AUTOSAR XML (schema 4-2-2)
package /AUTOLIV/SoftwareComponents/SAD
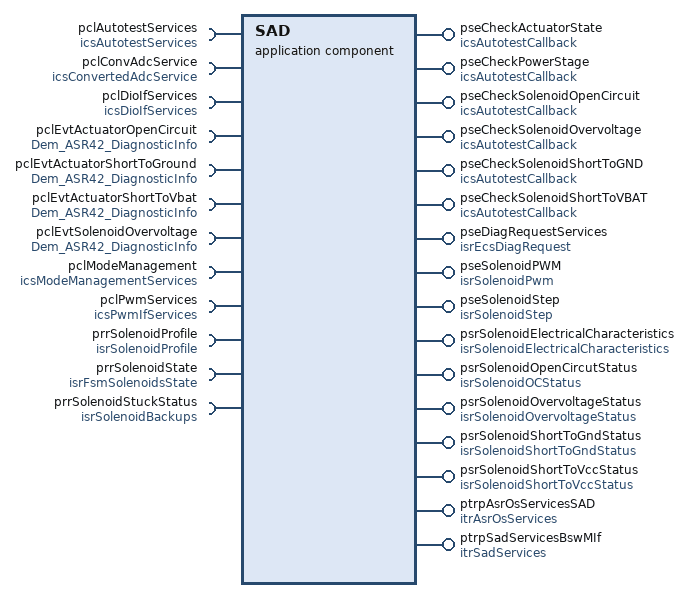
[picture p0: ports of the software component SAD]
  application sw component type SAD: category=SWC  # SAD_AC_SolenoidAbstractionDriver
    12 x require port:
      pclAutotestServices: required-com-specs=[GetCriticalAutoTestsReachedFlag, GetTestResult], required-interface=icsAutotestServices  # # Architecture Element ID ARCH_SW_SAD_pclAutotestServices # Description - The interface shall be used to read different autotests results by passing the {Autotest Id} to the input parameter and reading the {Autotest Result} output parameter. # Data Flow ## Inputs - {Autotest Id} • Can be: - One of the autotest id value between [0...17] ## Outputs - {Autotest Result} • Can be OK, NOK, NOT DECIDED, NON_EXISTENT, BAD_CONDITIONS #Linked Runnable - SAD_CheckSolenoidShortToVBATAutotest - SAD_CheckSolenoidShortToGNDAutotest - SAD_CheckSolenoidOpenCircuitAutotest - SAD_CheckSolenoidOvervoltage - SAD_CheckPowerStage # Traceability
      pclConvAdcService: client-com-spec=getMeasure, required-interface=icsConvertedAdcService  # # Architecture Element ID ARCH_SW_SAD_pclConvAdcService # Description - The interface shall be used to read the KL30 voltage level in mV # Data Flow ## Inputs ## Outputs - {KL30 Voltage in mV} #Linked Runnable - SAD_runMainFunction - SAD_CheckSolenoidOpenCircuitAutotest - SAD_CheckSolenoidShortToGNDAutotest - SAD_CheckSolenoidShortToVBATAutotest - SAD_CheckSolenoidOvervoltage # Traceability
      pclDioIfServices: required-com-specs=[ReadChannel, WriteChannel], required-interface=icsDioIfServices  # # Architecture Element ID ARCH_SW_SAD_pclDioIfServices # Description - The interface shall be used to set the {Digital Pin Level} of a certain {Pin ID}; - The interface shall be used to Read the {Pin ID} of a certain {Pin Digital Level}; # Data Flow ## Inputs - {Digital Pin Level} - Can be STD_HIGH, STD_LOW - {Pin ID} - Can be: - DIOIF_CH_EN_CS_X - The Solenoid enable pin wher 'X' is the ID of solenoid; - DIOIF_CH_ON_OFF_POWER - The ID of general swithc of solenoids circuit; - DIOIF_CH_EN_BOOST - The ID of enebling boost circuit; ## Outputs - {Pin Digital Level} - Can be STD_HIGH, STD_LOW #Linked Runnable - SAD_CheckPowerStage - SAD_runMainFunction # Traceability DOM_eCS_TF_R_173;
      pclEvtActuatorOpenCircuit: required-interface=Dem_ASR42_DiagnosticInfo  # # Architecture Element ID - ARCH_SW_SAD_pclEvtActuatorOpenCircuit # Description - The RTE port shall be used to read the status of the Open Circuit Event using the output variable {Event Status}. # Data Flow ## Inputs ## Outputs - {Event Status} • Can be one or more combination of the following values: - DEM_UDS_STATUS_TF - DEM_UDS_STATUS_TFTOC - DEM_UDS_STATUS_PDTC - DEM_UDS_STATUS_CDTC - DEM_UDS_STATUS_TNCSLC - DEM_UDS_STATUS_TFSLC - DEM_UDS_STATUS_TNCTOC - DEM_UDS_STATUS_WIR # Linked Runnable - SAD_CheckSolenoidOpenCircuitAutotest #Traceability
        required-com-specs:
          GetEventStatus
          GetEventFailed
          GetEventTested
          GetDTCOfEvent
          GetFaultDetectionCounter
          GetEventFreezeFrameData
          GetEventExtendedDataRecord
          GetDebouncingOfEvent
          GetEventExtendedDataRecordEx
          GetEventFreezeFrameDataEx
      pclEvtActuatorShortToGround: required-interface=Dem_ASR42_DiagnosticInfo  # # Architecture Element ID - ARCH_SW_SAD_pclEvtActuatorShortToGround # Description - The RTE port shall be used to read the status of the Short Circuit to Ground Event using the output variable {Event Status}. # Data Flow ## Inputs ## Outputs - {Event Status} • Can be one or more combination of the following values: - DEM_UDS_STATUS_TF - DEM_UDS_STATUS_TFTOC - DEM_UDS_STATUS_PDTC - DEM_UDS_STATUS_CDTC - DEM_UDS_STATUS_TNCSLC - DEM_UDS_STATUS_TFSLC - DEM_UDS_STATUS_TNCTOC - DEM_UDS_STATUS_WIR # Linked Runnable - SAD_CheckSolenoidShortToGNDAutotest #Traceability
        required-com-specs:
          GetEventStatus
          GetEventFailed
          GetEventTested
          GetDTCOfEvent
          GetFaultDetectionCounter
          GetEventFreezeFrameData
          GetEventExtendedDataRecord
          GetDebouncingOfEvent
          GetEventExtendedDataRecordEx
          GetEventFreezeFrameDataEx
      pclEvtActuatorShortToVbat: required-interface=Dem_ASR42_DiagnosticInfo  # # Architecture Element ID - ARCH_SW_SAD_pclEvtActuatorShortToVbat # Description - The RTE port shall be used to read the status of the Short Circuit to Ground Event using the output variable {Event Status}. # Data Flow ## Inputs ## Outputs - {Event Status} • Can be one or more combination of the following values: - DEM_UDS_STATUS_TF - DEM_UDS_STATUS_TFTOC - DEM_UDS_STATUS_PDTC - DEM_UDS_STATUS_CDTC - DEM_UDS_STATUS_TNCSLC - DEM_UDS_STATUS_TFSLC - DEM_UDS_STATUS_TNCTOC - DEM_UDS_STATUS_WIR # Linked Runnable - SAD_CheckSolenoidShortToVBATAutotest #Traceability
        required-com-specs:
          GetEventStatus
          GetEventFailed
          GetEventTested
          GetDTCOfEvent
          GetFaultDetectionCounter
          GetEventFreezeFrameData
          GetEventExtendedDataRecord
          GetDebouncingOfEvent
          GetEventExtendedDataRecordEx
          GetEventFreezeFrameDataEx
      pclEvtSolenoidOvervoltage: required-interface=Dem_ASR42_DiagnosticInfo  # # Architecture Element ID - ARCH_SW_SAD_pclEvtSolenoidOvervoltage # Description - The RTE port shall be used to read the status of the Solenoid Over Voltage Event using the output variable {Event Status}. # Data Flow ## Inputs ## Outputs - {Event Status} • Can be one or more combination of the following values: - DEM_UDS_STATUS_TF - DEM_UDS_STATUS_TFTOC - DEM_UDS_STATUS_PDTC - DEM_UDS_STATUS_CDTC - DEM_UDS_STATUS_TNCSLC - DEM_UDS_STATUS_TFSLC - DEM_UDS_STATUS_TNCTOC - DEM_UDS_STATUS_WIR # Linked Runnable - SAD_CheckSolenoidOvervoltage #Traceability
        required-com-specs:
          GetEventStatus
          GetEventFailed
          GetEventTested
          GetDTCOfEvent
          GetFaultDetectionCounter
          GetEventFreezeFrameData
          GetEventExtendedDataRecord
          GetDebouncingOfEvent
          GetEventExtendedDataRecordEx
          GetEventFreezeFrameDataEx
      pclModeManagement: client-com-spec=CheckModeStatus, required-interface=icsModeManagementServices  # # Architecture Element ID ARCH_SW_SAD_pclModeManagement # Description - The interface shall be used to read different statuses regarding the solenoid states by passing the {Mode Status Flag} to the input parameter and reading the {Mode Status} output parameter. # Data Flow ## Inputs - {Mode Status Flag} • Can be: - CRITICAL_AUTOTESTS_IN_PROGRESS; - NVM_BLOCK_RESTORE_IN_PROGRESS; - SOLENOID_X_DISABLED; - SOLENOID_X_BUCKLE_LATCHED; - SOLENOID_X_UNLOCK_CONFIRMED; - ECU_PERMANENT_HW_ERROR; - ECU_SPORADIC_ERROR; - CAN_INHIB_STATUS; * Where X represents the solenoid number and can take the value between [1..6]; ## Outputs - {Mode Status} • Can be TRUE, FALSE #Linked Runnable - SAD_runMainFunction # Traceability
      pclPwmServices: required-com-specs=[DisablePWM, EnablePWM, SetDutyCycle], required-interface=icsPwmIfServices  # # Architecture Element ID ARCH_SW_SAD_pclPwmServices # Description - The interface shall be used to set the {PWM Duty Cycle Value} of a certain {Solenoid Channel ID} # Data Flow ## Inputs - {Solenoid Channel ID} - {PWM Duty Cycle Value} ## Outputs #Linked Runnable - SAD_runMainFunction # Traceability
      prrSolenoidProfile: nonqueued-receiver-com-spec{data-element=au8SelectedProfile, enable-update=true, init-value=6 x KU8_PROFILE_UNLOCK}, required-interface=isrSolenoidProfile  # # Architecture Element ID ARCH_SW_SAD_prrSolenoidProfile # Description - The interface shall be used to read the profile(collection of steps) nb. that should be executed by the SAD module for each solenoid. # Data Flow ## Inputs ## Outputs - {Profile for Solenoid x} (valid for all solenoids) • Can be: - 00h - UNLOCK; - 01h - BACKUP; - 02h - DIAGNOSTIC; - FFh - NO_PROFILE; #Linked Runnable - SAD_runMainFunction # Traceability
      prrSolenoidState: nonqueued-receiver-com-spec{data-element=au8SolenoidState, init-value=6 x KU8_LOCK_STATE}, required-interface=isrFsmSolenoidsState
      prrSolenoidStuckStatus: nonqueued-receiver-com-spec{data-element=au8SolenoidIsStuck, enable-update=true, init-value=6 x 0}, required-interface=isrSolenoidBackups  # # Architecture Element ID - ARCH_SW_SAD_prrSolenoidStuckStatus_SAD_checkActuatorState # Description - The runnable shall read on {Solenoid Stuck Status} the current stuck status of each solenoid. # Data Flow ## Inputs ## Outputs - {Solenoid Stuck Status} - Can be KU8_FALSE - if the solenoid is NOT stuck; - Can be KU8_TRUE - if the solenoid is stuck; # Linked Runnable - SAD_checkActuatorState #Traceability DOM_eCS_TF_H_233, DOM_eCS_TF_H_234, DOM_eCS_TF_H_235
    16 x provide port:
      pseCheckActuatorState: server-com-spec{operation=AutotestCallback, queue-length=1}, provided-interface=icsAutotestCallback  # # Architecture Element ID - ARCH_SW_SAD_pseCheckActuatorState_SAD_checkActuatorState # Description - The auto-test shall detect if the solenoid lever is mechanically blocked - If the number of executed backup profiles from the {Nb. of Executed Backups} input parameter is higher or equal than the {Executed Backup Threshold} then the auto-test shall return NOK on the {Autotest Result} output parameter - If the buckle status coresponding to the tested solenoid is not latched, then the auto-test result shall be forced to OK - If the solenoid is disabled via the {Solenoid Variant Coding} then the actuator blocked conditions will not be checked # Data Flow ## Inputs - {Nb. of Executed Backups} - {Executed Backup Threshold} - {Solenoid Variant Coding} - {Buckle Status} ## Outputs - {Autotest Result} - Can be one of the following values: OK, NOK, NOT DECIDED # Linked Runnable - SAD_checkActuatorState #Traceability DOM_eCS_TF_H_233, DOM_eCS_TF_H_234, DOM_eCS_TF_H_235
      pseCheckPowerStage: server-com-spec{operation=AutotestCallback, queue-length=1}, provided-interface=icsAutotestCallback  # # Architecture Element ID - ARCH_SW_SAD_pseCheckPowerStage_SAD_CheckPowerStage # Description - The auto-test shall check the states of relevant pins involved in the solenoid control circuit. The auto-test will check the next situations: - If profile UNLOCK or BACKUP is active and reached the finishing step: - On-Off pin should be HIGH; - Boost Enable pin should be LOW; - Solenoid enable pin should be LOW; - If profile DIAGNOSTIC is active : - On-Off pin should be HIGH; - Boost Enable pin should be HIGH; - Solenoid enable pin should be LOW; - If profile LOCK is active on all enabled solenoids: - On-Off pin should be LOW; - Boost Enable pin should be HIGH; - Solenoid enable pin should be HIGH; # Data Flow ## Inputs ## Outputs - {Autotest Result} - Can be one of the following values: OK, NOK, NOT DECIDED # Linked Runnable - SAD_CheckPowerStage #Traceability DOM_eCS_TF_H_398 DOM_eCS_TF_H_399 DOM_eCS_TF_H_400 DOM_eCS_TF_H_401 DOM_eCS_TF_H_402 DOM_eCS_TF_H_403 DOM_eCS_TF_H_378
      pseCheckSolenoidOpenCircuit: server-com-spec{operation=AutotestCallback, queue-length=1}, provided-interface=icsAutotestCallback  # # Architecture Element ID - ARCH_SW_SAD_pseCheckSolenoidOpenCircuit_SAD_CheckSolenoidOpenCircuitAutotest # Description - The auto-test shall detect for all conected and configured solenoids if they are electrically conected. - In order to detect an open-circuit hardware fault, all measurements on solenoid ADC lines shall be done with unlock profile or diagnostic profile active. - If the measured solenoid voltage is lower or equal than {NVP_u16OpenCircuitUnlockHighThrs} when unlock profile is active and step profile is different than infinite step, than autotest shall return OK. - If the measured solenoid voltage is greater than {NVP_u16OpenCircuitUnlockHighThrs} when unlock profile is active and step profile is different than infinite step, than autotest shall return NOK. - If the measured solenoid voltage is in range between +25% of {VBATMeasuredVoltage} and -25% of {VBATMeasuredVoltage} when unlock profile is active and step profile is equal to infinite step, than autotest shall return OK. - If the measured solenoid voltage is not in range between +25% of {VBATMeasuredVoltage} and -25% of {VBATMeasuredVoltage} when unlock profile is active and step profile is equal to infinite step, than autotest shall return NOK. - If the measured solenoid voltage is in range between +20% of {NVP_u16OpenCircuitDiagProfThrs} and -20% of {NVP_u16OpenCircuitDiagProfThrs} when diagnostic profile is active, than autotest shall return OK. - If the measured solenoid voltage is not in range between +20% of {NVP_u16OpenCircuitDiagProfThrs} and -20% of {NVP_u16OpenCircuitDiagProfThrs} when diagnostic profile is active, than autotest shall NOK. - If unlock profile or diagnostic profile is not active, than autotest shall return last valid autotest result. # Data Flow ## Inputs - {NVP_u16OpenCircuitUnlockHighThrs} - {VBATMeasuredVoltage} - {NVP_u16OpenCircuitDiagProfThrs} ## Outputs - {Autotest Result} - Can be one of the following values: OK, NOK, NOT DECIDED # Linked Runnable - SAD_CheckSolenoidOpenCircuitAutotest #Traceability DOM_eCS_TF_H_260, DOM_eCS_TF_H_261, DOM_eCS_TF_H_259, DOM_eCS_TF_H_265, DOM_eCS_TF_H_256
      pseCheckSolenoidOvervoltage: server-com-spec{operation=AutotestCallback, queue-length=1}, provided-interface=icsAutotestCallback  # # Architecture Element ID - ARCH_SW_SAD_pseCheckSolenoidOvervoltage_SAD_CheckSolenoidOvervoltage # Description - The auto-test shall detect all connected and configured solenoids if they didn't exceed an NVP Configurable voltage Threshold when they have an active profile: - If UNLOCK or BACKUP profile is active and the infinite step is reached: - If the measured solenoid voltage is lower than NVP_u16OvervoltageUnlockProfThrs when unlock profile is active, than autotest shall return OK. - If the measured solenoid voltage is greater or equal to NVP_u16OvervoltageUnlockProfThrs when unlock profile is active, than autotest shall return NOK. - If DIAGNOSTIC profile is active : - If the measured solenoid voltage is lower than NVP_u16OvervoltageDiagProfThrs when diagnostic profile is active, than autotest shall return OK. - If the measured solenoid voltage is greater or equal to NVP_u16OvervoltageDiagProfThrs when diagnostic profile is active, than autotest shall return NOK. - If NO profile is active (LOCK): - If unlock profile or diagnostic profile is not active, than autotest shall return last valid autotest result. # Data Flow ## Outputs - {Autotest Result} - Can be one of the following values: OK, NOK, NOT DECIDED # Linked Runnable - SAD_CheckSolenoidOvervoltage #Traceability DOM_eCS_TF_H_392 DOM_eCS_TF_H_393 DOM_eCS_TF_H_394 DOM_eCS_TF_H_396 DOM_eCS_TF_H_397 DOM_eCS_TF_H_381
      pseCheckSolenoidShortToGND: server-com-spec{operation=AutotestCallback, queue-length=1}, provided-interface=icsAutotestCallback  # # Architecture Element ID - ARCH_SW_SAD_pseCheckSolenoidShortToGND_SAD_CheckSolenoidShortToGNDAutotest # Description - The auto-test shall detect for all conected and configured solenoids if they have electrical . - In order to detect an open-circuit hardware fault, all measurements on solenoid ADC lines shall be done with unlock profile or diagnostic profile active. - If the measured solenoid voltage is greater or equal than NVP_u16ShortToGNDUnlockProfThrs when unlock profile is active, than autotest shall return OK. - If the measured solenoid voltage is lower than NVP_u16ShortToGNDUnlockProfThrs when unlock profile is active, than autotest shall return NOK. - If the measured solenoid voltage is greater or equal than NVP_u16ShortToGNDDiagProfThrs when diagnostic profile is active, than autotest shall return OK. - If the measured solenoid voltage is lower than NVP_u16ShortToGNDDiagProfThrs when diagnostic profile is active, than autotest shall return NOK. - If unlock profile or diagnostic profile is not active, than autotest shall return last valid autotest result. # Data Flow ## Inputs - {NVP_u16ShortToGNDUnlockProfThrs} - {NVP_u16ShortToGNDDiagProfThrs} ## Outputs - {Autotest Result} - Can be one of the following values: OK, NOK, NOT DECIDED # Linked Runnable - SAD_CheckSolenoidShortToGNDAutotest #Traceability DOM_eCS_TF_H_262, DOM_eCS_TF_H_263, DOM_eCS_TF_H_266, DOM_eCS_TF_H_267, DOM_eCS_TF_H_257
      pseCheckSolenoidShortToVBAT: server-com-spec{operation=AutotestCallback, queue-length=1}, provided-interface=icsAutotestCallback  # # Architecture Element ID - ARCH_SW_SAD_pseCheckSolenoidShortToVBAT_SAD_CheckSolenoidShortToVBATAutotest # Description - The auto-test shall detect for all conected and configured solenoids if they are electrically shorted to VBAT. - In order to detect an open-circuit hardware fault, all measurements on solenoid ADC lines shall be done with no profile active. - If the measured solenoid voltage in milivolts is in range between +20% of KL30 ADC Measurements in milivolts and -20% of KL30 ADC Measurements in milivolts when no profile is active, than autotest shall return NOK. - If the measured solenoid voltage in milivolts is not in range between +20% of KL30 ADC Measurements in milivolts and -20% of KL30 ADC Measurements in milivolts when no profile is active, than autotest shall return OK. - If unlock profile or diagnostic profile is active, than autotest shall return last valid autotest result. # Data Flow ## Inputs - {KL30 ( VBAT ) ADC Measurements in milivolts} ## Outputs - {Autotest Result} - Can be one of the following values: OK, NOK, NOT DECIDED # Linked Runnable - SAD_CheckSolenoidShortToVBATAutotest #Traceability DOM_eCS_TF_H_264, DOM_eCS_TF_H_268, DOM_eCS_TF_H_258
      pseDiagRequestServices: provided-interface=isrEcsDiagRequest  # # Architecture Element ID - ARCH_SW_SAD_pseDiagRequestServices # Description - The RTE port shall be used to set the value of the diagnostic request paramenter when the method is called by writing on the output variable {Diag Req}. - For a more safe transmision, the complement of the diagnostic request must be transmitted by writing on the output variable {Diag Req Complement}. # Data Flow ## Inputs ## Outputs - {Diag Req} - Can be one of the following values: NO_DIAG_REQUEST, DIAG_PROFILE_REQUEST_ON; - {Diag Req Complement}. - Can be one of the following values: ~NO_DIAG_REQUEST, ~DIAG_PROFILE_REQUEST_ON; # Linked Runnable - SAD_runMainFunction #Traceability
        provided-com-specs:
          data-element=au8DiagReq, uses-end-to-end-protection=0, init-value=6 x KU8_NO_DIAG_REQUEST
          data-element=au8DiagReqComplement, uses-end-to-end-protection=0, init-value=6 x KU8_NO_DIAG_REQUEST_COMPLEMENT
      pseSolenoidPWM: nonqueued-sender-com-spec{data-element=au16Pwm, uses-end-to-end-protection=0, init-value=6 x 0}, provided-interface=isrSolenoidPwm  # # Architecture Element ID ARCH_SW_SAD_pseSolenoidPWM # Description - The runnable shall be used to compute the target PWM value and report it to the rest of the Application - The target PWM value shall be computed based on the KL30 Voltage and step definiton # Data Flow ## Inputs - {PWM Duty Cycle Value} • Can take the values between [0x0000... 0x8000] ## Outputs #Linked Runnable - SAD_runMainFunction # Traceability
      pseSolenoidStep: nonqueued-sender-com-spec{data-element=au8CurrentStep, uses-end-to-end-protection=0, init-value=6 x 0}, provided-interface=isrSolenoidStep  # # Architecture Element ID ARCH_SW_SAD_pseSolenoidStep # Description - The runnable shall extract the step definition in the RAM copy of the NvM Block - Each step shall contain the following information: - Duration - Consign(the PWM value that the uC must output) - Consign Type (unit in which consign is configured, will always be PWM) - Ramp option (if the PWM value should be reached in a ramp) - Infinite duration option (if the step should continue until another request is received) - Trigger off option (if the step should end when unlock detection was confirmed) # Data Flow ## Inputs - {Profile Definition} ## Outputs - {Current Step for Solenoid x} (valid for all solenoids) - Can be - 00h - Step 0 - 01h - Step 1 - 02h - Step 2 - 03h - Step 3 - 04h - Step 4 - 05h - Step 5 - 06h - Step 6 - 07h - Step 7 - FFh - NO_STEP #Linked Runnable - SAD_runMainFunction # Traceability
      psrSolenoidElectricalCharacteristics: nonqueued-sender-com-spec{data-element=au32SolenoidmATarget, uses-end-to-end-protection=0, init-value=6 x 0}, provided-interface=isrSolenoidElectricalCharacteristics  # # Architecture Element ID ARCH_SW_SAD_psrSolenoidElectricalCharacteristics # Description - The interface shall save the {Current Target} value in [mA] extracted from the currently executing step of the active profile. # Data Flow ## Inputs - {Current Target} - Can be : any value in range of 32 bit variable; ## Outputs - None #Linked Runnable - SAD_runMainFunction # Traceability
      psrSolenoidOpenCircutStatus: nonqueued-sender-com-spec{data-element=au8SolenoidAutotestStatus, uses-end-to-end-protection=0, init-value=6 x KU8_SOLENOID_ELECTRICAL_AT_PASSED}, provided-interface=isrSolenoidOCStatus  # # Architecture Element ID ARCH_SW_SAD_psrSolenoidOpenCircutStatus_SAD_CheckSolenoidOpenCircuitAutotest # Description - The runnable shall write an array representing the error status on the {Status of solenoids} output parameter regarding an open circuit fault for each solenoid. # Data Flow ## Inputs - None ## Outputs - {Status of solenoids} (valid for all solenoids) - Can be : - 00h - KU8_SOLENOID_ELECTRICAL_AT_PASSED - 01h - KU8_SOLENOID_ELECTRICAL_AT_FAILED #Linked Runnable - SAD_CheckSolenoidOpenCircuitAutotest # Traceability DOM_eCS_TF_H_371 DOM_eCS_TF_H_372
      psrSolenoidOvervoltageStatus: nonqueued-sender-com-spec{data-element=au8SolenoidOvervoltageStatus, uses-end-to-end-protection=0, init-value=6 x KU8_SOLENOID_ELECTRICAL_AT_PASSED}, provided-interface=isrSolenoidOvervoltageStatus  # # Architecture Element ID ARCH_SW_SAD_psrSolenoidOvervoltageStatus # Description - The runnable shall write an array representing the error status on the {Status of solenoids} output parameter regarding a Over Voltage fault for each solenoid. # Data Flow ## Inputs - None ## Outputs - {Status of solenoids} (valid for all solenoids) - Can be : - 00h - KU8_SOLENOID_ELECTRICAL_AT_PASSED - 01h - KU8_SOLENOID_ELECTRICAL_AT_FAILED #Linked Runnable - SAD_CheckSolenoidOvervoltage # Traceability
      psrSolenoidShortToGndStatus: nonqueued-sender-com-spec{data-element=au8SolenoidAutotestStatus, uses-end-to-end-protection=0, init-value=6 x KU8_SOLENOID_ELECTRICAL_AT_PASSED}, provided-interface=isrSolenoidShortToGndStatus  # # Architecture Element ID ARCH_SW_SAD_psrSolenoidShortToGndStatus # Description - The runnable shall write an array representing the error status on the {Status of solenoids} output parameter regarding a short circuit to Ground fault for each solenoid. # Data Flow ## Inputs - None ## Outputs - {Status of solenoids} (valid for all solenoids) - Can be : - 00h - KU8_SOLENOID_ELECTRICAL_AT_PASSED - 01h - KU8_SOLENOID_ELECTRICAL_AT_FAILED #Linked Runnable - SAD_CheckSolenoidShortToGNDAutotest # Traceability
      psrSolenoidShortToVccStatus: nonqueued-sender-com-spec{data-element=au8SolenoidAutotestStatus, uses-end-to-end-protection=0, init-value=6 x KU8_SOLENOID_ELECTRICAL_AT_PASSED}, provided-interface=isrSolenoidShortToVccStatus  # # Architecture Element ID ARCH_SW_SAD_psrSolenoidShortToVccStatus # Description - The runnable shall write an array representing the error status on the {Status of solenoids} output parameter regarding a short circuit to Vcc fault for each solenoid. # Data Flow ## Inputs - None ## Outputs - {Status of solenoids} (valid for all solenoids) - Can be : - 00h - KU8_SOLENOID_ELECTRICAL_AT_PASSED - 01h - KU8_SOLENOID_ELECTRICAL_AT_FAILED #Linked Runnable - SAD_CheckSolenoidShortToVBATAutotest # Traceability DOM_eCS_TF_H_374 DOM_eCS_TF_H_375
      ptrpAsrOsServicesSAD: provided-interface=itrAsrOsServices  # # Architecture Element ID ARCH_SW_SAD_ptrpAsrOsServices # Description - The runnable shall be called by the Autosar OS each 1mS # Data Flow ## Inputs ## Outputs #Linked Runnable - SAD_runMainFunction # Traceability FUSA_SM_S32K1XXSM_59, FUSA_SM_S32K1XXSM_128, FUSA_SM_S32K1XXSM_132, FUSA_SM_S32K1XXSM_148, DOM_eCS_TF_R_158, DOM_eCS_TF_R_174, DOM_eCS_TF_R_175, DOM_eCS_TF_R_176
      ptrpSadServicesBswMIf: provided-interface=itrSadServices  # # Architecture Element ID ARCH_SW_Sad_ptrpSadServicesBswMIf_SAD_Init # Description - The SAD_Init runnable shall be called during the initialization in the BswM_OnStartComEffective runnable # Data Flow # Linked Runnable - SAD_Init # Traceability
